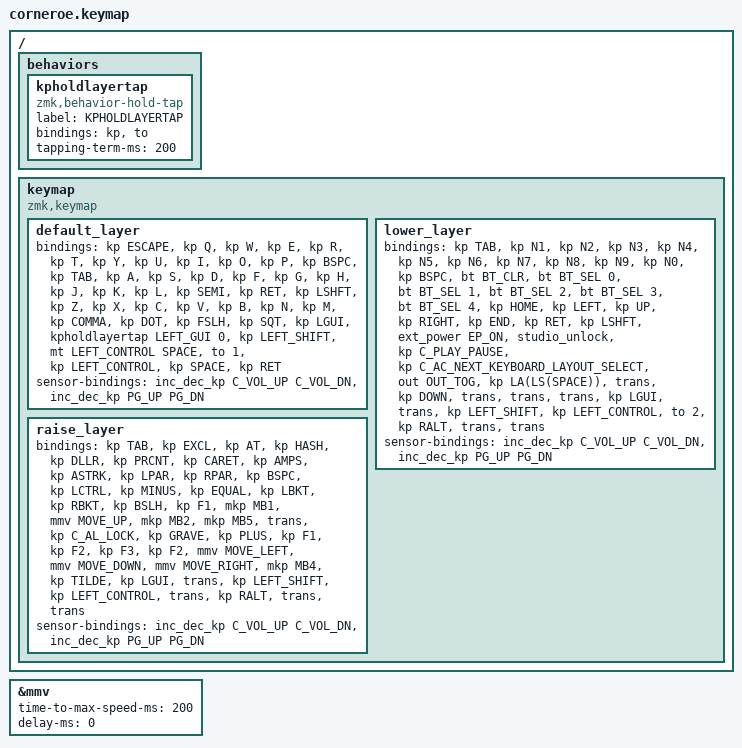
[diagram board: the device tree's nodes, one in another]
/*
 * Copyright (c) 2020 The ZMK Contributors
 *
 * SPDX-License-Identifier: MIT
 */

#include <dt-bindings/zmk/mouse.h>
#include <behaviors.dtsi>
#include <dt-bindings/zmk/bt.h>
#include <dt-bindings/zmk/ext_power.h>
#include <dt-bindings/zmk/keys.h>
#include <dt-bindings/zmk/outputs.h>
#include <dt-bindings/zmk/pointing.h>

#define ZMK_MOUSE_DEFAULT_MOVE_VAL 3000  // 600
#define ZMK_MOUSE_DEFAULT_SCRL_VAL 20    // 10

&mmv {
    time-to-max-speed-ms = <200>;
    delay-ms = <0>;
};

/ {
    behaviors {
        kpholdlayertap: kpholdlayertap {
            compatible = "zmk,behavior-hold-tap";
            label = "KPHOLDLAYERTAP";
            bindings = <&kp>, <&to>;

            #binding-cells = <2>;
            tapping-term-ms = <200>;
        };
    };

    keymap {
        compatible = "zmk,keymap";

        default_layer {
            // -----------------------------------------------------------------------------------------
            // |  TAB |  Q  |  W  |  E  |  R  |  T  |   |  Y  |  U   |  I  |  O  |  P  | BSPC |
            // | CTRL |  A  |  S  |  D  |  F  |  G  |   |  H  |  J   |  K  |  L  |  ;  |  '   |
            // | SHFT |  Z  |  X  |  C  |  V  |  B  |   |  N  |  M   |  ,  |  .  |  /  | ESC  |
            //                    | GUI | LWR | SPC |   | ENT | RSE  | ALT |

            bindings = <
&kp ESCAPE  &kp Q  &kp W  &kp E  &kp R  &kp T  &kp Y  &kp U  &kp I  &kp O  &kp P  &kp BSPC  &kp TAB  &kp A  &kp S  &kp D  &kp F  &kp G  &kp H  &kp J  &kp K  &kp L  &kp SEMI  &kp RET  &kp LSHFT  &kp Z  &kp X  &kp C  &kp V  &kp B  &kp N  &kp M  &kp COMMA  &kp DOT  &kp FSLH  &kp SQT  &kp LGUI  &kpholdlayertap LEFT_GUI 0  &kp LEFT_SHIFT  &mt LEFT_CONTROL SPACE  &to 1  &kp LEFT_CONTROL  &kp SPACE  &kp RET
            >;

            sensor-bindings = <&inc_dec_kp C_VOL_UP C_VOL_DN &inc_dec_kp PG_UP PG_DN>;
        };

        lower_layer {
            // -----------------------------------------------------------------------------------------
            // |  TAB |  1  |  2  |  3  |  4  |  5  |   |  6  |  7  |  8  |  9  |  0  | BSPC |
            // | BTCLR| BT1 | BT2 | BT3 | BT4 | BT5 |   | LFT | DWN |  UP | RGT |     |      |
            // | SHFT |     |     |     |     |     |   |     |     |     |     |     |      |
            //                    | GUI |     | SPC |   | ENT |     | ALT |

            bindings = <
&kp TAB  &kp N1  &kp N2  &kp N3  &kp N4  &kp N5  &kp N6  &kp N7  &kp N8  &kp N9  &kp N0  &kp BSPC  &bt BT_CLR  &bt BT_SEL 0  &bt BT_SEL 1  &bt BT_SEL 2  &bt BT_SEL 3  &bt BT_SEL 4  &kp HOME  &kp LEFT  &kp UP  &kp RIGHT  &kp END  &kp RET  &kp LSHFT  &ext_power EP_ON  &studio_unlock  &kp C_PLAY_PAUSE  &kp C_AC_NEXT_KEYBOARD_LAYOUT_SELECT  &out OUT_TOG  &kp LA(LS(SPACE))  &trans  &kp DOWN  &trans  &trans  &trans  &kp LGUI  &trans  &kp LEFT_SHIFT  &kp LEFT_CONTROL  &to 2  &kp RALT  &trans  &trans
            >;

            sensor-bindings = <&inc_dec_kp C_VOL_UP C_VOL_DN &inc_dec_kp PG_UP PG_DN>;
        };

        raise_layer {
            // -----------------------------------------------------------------------------------------
            // |  TAB |  !  |  @  |  #  |  $  |  %  |   |  ^  |  &  |  *  |  (  |  )  | BSPC |
            // | CTRL |     |     |     |     |     |   |  -  |  =  |  [  |  ]  |  \  |  `   |
            // | SHFT |     |     |     |     |     |   |  _  |  +  |  {  |  }  | "|" |  ~   |
            //                    | GUI |     | SPC |   | ENT |     | ALT |

            bindings = <
&kp TAB  &kp EXCL  &kp AT  &kp HASH  &kp DLLR  &kp PRCNT  &kp CARET  &kp AMPS  &kp ASTRK  &kp LPAR  &kp RPAR  &kp BSPC  &kp LCTRL  &kp MINUS  &kp EQUAL  &kp LBKT  &kp RBKT  &kp BSLH  &kp F1  &mkp MB1  &mmv MOVE_UP  &mkp MB2  &mkp MB5  &trans  &kp C_AL_LOCK  &kp GRAVE  &kp PLUS  &kp F1  &kp F2  &kp F3  &kp F2  &mmv MOVE_LEFT  &mmv MOVE_DOWN  &mmv MOVE_RIGHT  &mkp MB4  &kp TILDE  &kp LGUI  &trans  &kp LEFT_SHIFT  &kp LEFT_CONTROL  &trans  &kp RALT  &trans  &trans
            >;

            sensor-bindings = <&inc_dec_kp C_VOL_UP C_VOL_DN &inc_dec_kp PG_UP PG_DN>;
        };
    };
};
